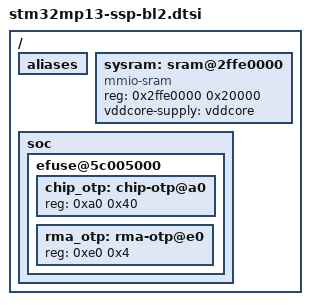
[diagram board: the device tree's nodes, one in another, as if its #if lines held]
// SPDX-License-Identifier: (GPL-2.0+ OR BSD-3-Clause)
/*
 * Copyright (C) STMicroelectronics 2020 - All Rights Reserved
 */

/ {
	aliases {
		/delete-property/ mmc0;
	};

	sysram: sram@2ffe0000 {
		compatible = "mmio-sram";
		reg = <0x2ffe0000 0x20000>;
		vddcore-supply = <&vddcore>;
	};

	soc {
		efuse@5c005000 {
			chip_otp: chip-otp@a0 {
				reg = <0xa0 0x40>;
			};
			rma_otp: rma-otp@e0 {
				reg = <0xe0 0x4>;
			};
		};

#if STM32MP_UART_PROGRAMMER
		/delete-node/ usb-otg@49000000;
#endif
		/delete-node/ spi@58003000;
		/delete-node/ mmc@58005000;
		/delete-node/ mmc@58007000;
#if STM32MP_UART_PROGRAMMER
		/delete-node/ usbh-ohci@5800c000;
		/delete-node/ usbh-ehci@5800d000;
#endif
#if STM32MP_UART_PROGRAMMER
		/delete-node/ usbphyc@5a006000;
#endif
	};
};
